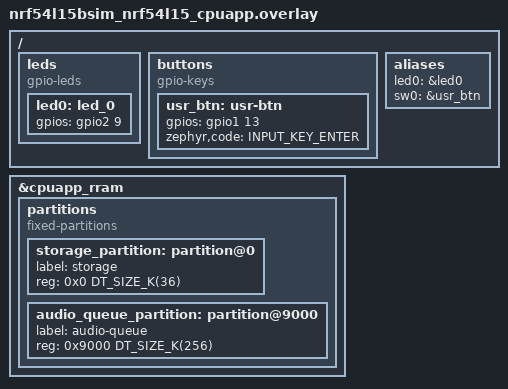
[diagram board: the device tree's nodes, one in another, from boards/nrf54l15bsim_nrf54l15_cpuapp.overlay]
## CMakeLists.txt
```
# Copyright (c) Meta Platforms, Inc. and affiliates.
#
# Licensed under the Apache License, Version 2.0 (the "License");
# you may not use this file except in compliance with the License.
# You may obtain a copy of the License at
#
#     http://www.apache.org/licenses/LICENSE-2.0
#
# Unless required by applicable law or agreed to in writing, software
# distributed under the License is distributed on an "AS IS" BASIS,
# WITHOUT WARRANTIES OR CONDITIONS OF ANY KIND, either express or implied.
# See the License for the specific language governing permissions and
# limitations under the License.

cmake_minimum_required(VERSION 3.20.0)

find_package(Zephyr REQUIRED HINTS $ENV{ZEPHYR_BASE})
project(muse_gadget_zephyr)

# The XIAO's flash map (mcuboot, slot0, slot1, storage) boots through MCUboot:
# without it the image would sit at slot0 with nothing at 0 to start it.
if(CONFIG_BOARD_XIAO_NRF54L15 AND NOT CONFIG_BOOTLOADER_MCUBOOT)
  message(FATAL_ERROR "Build the XIAO nRF54L15 with --sysbuild: it boots through MCUboot "
    "(sysbuild.conf). See AGENTS.md, Build.")
endif()

include(${CMAKE_CURRENT_SOURCE_DIR}/cmake/mg_common.cmake)

target_include_directories(app PRIVATE ${MG_PROTOCOLS} src)

target_sources(app PRIVATE
  src/main.c
  src/mg_core.c
  src/mg_settings.c
  src/mg_session.c
  src/mg_identity.c
  src/mg_json.c
  src/mg_psa.c
  src/mg_setup.c
  src/mg_setup_crypto.c
  src/mg_setup_store.c
  src/mg_token_proof.c
  src/mg_codec.c
  src/mg_audio.c
  src/mg_hpf.c
  src/mg_ble.c
  src/mg_connparam.c
  src/mg_throughput.c
  src/mg_led.c
  src/mg_button.c
)
target_sources_ifdef(CONFIG_MG_AUDIO_QUEUE app PRIVATE src/mg_queue.c)
target_sources_ifdef(CONFIG_MG_SECURE app PRIVATE src/mg_crypto.c src/mg_pairing.c)
target_sources_ifdef(CONFIG_MG_BATTERY_ADC app PRIVATE src/mg_battery.c)
target_sources_ifdef(CONFIG_MG_NUS app PRIVATE src/mg_nus.c)
target_sources_ifdef(CONFIG_MG_DFU app PRIVATE src/mg_ota.c)
target_sources_ifdef(CONFIG_MG_BENCH app PRIVATE src/mg_bench.c)
target_sources_ifdef(CONFIG_MG_AUDIO_SRC_DMIC app PRIVATE src/mg_audio_dmic.c)
target_sources_ifdef(CONFIG_MG_AUDIO_SRC_SYNTH app PRIVATE src/mg_audio_synth.c)
if(CONFIG_MG_BSIM_TESTS)
  add_subdirectory(${ZEPHYR_BASE}/tests/bsim/babblekit babblekit)
  target_link_libraries(app PRIVATE babblekit)
  target_sources(app PRIVATE tests/bsim/gadget_hooks.c)
  zephyr_include_directories(
    $ENV{BSIM_COMPONENTS_PATH}/libUtilv1/src $ENV{BSIM_COMPONENTS_PATH}/libPhyComv1/src)
endif()

mg_add_transcript(app)
mg_add_sbc(app)
if(CONFIG_MG_LC3)
  mg_add_lc3(app)
endif()
```

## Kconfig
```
# Copyright (c) Meta Platforms, Inc. and affiliates.
#
# Licensed under the Apache License, Version 2.0 (the "License");
# you may not use this file except in compliance with the License.
# You may obtain a copy of the License at
#
#     http://www.apache.org/licenses/LICENSE-2.0
#
# Unless required by applicable law or agreed to in writing, software
# distributed under the License is distributed on an "AS IS" BASIS,
# WITHOUT WARRANTIES OR CONDITIONS OF ANY KIND, either express or implied.
# See the License for the specific language governing permissions and
# limitations under the License.

mainmenu "Muse Gadget (Zephyr)"

rsource "Kconfig.mg"

# Device Information Service strings (mgcommands.h). The firmware revision
# is the app version from the VERSION file.
config BT_DIS_FW_REV_STR
	default "$(APPVERSION)"

config BT_DIS_MANUF_NAME_STR
	default "Seeed Studio"

config BT_DIS_MODEL_NUMBER_STR
	default "XIAO nRF54L15"

config BT_DIS_SW_REV_STR
	default "mg1"

# The connection parameters GAP advertises (Peripheral Preferred Connection
# Parameters) are the ones mg_connparam.c asks for.
config BT_PERIPHERAL_PREF_MIN_INT
	default MG_CONN_INTERVAL_MIN

config BT_PERIPHERAL_PREF_MAX_INT
	default MG_CONN_INTERVAL_MAX

config BT_PERIPHERAL_PREF_LATENCY
	default MG_CONN_LATENCY

config BT_PERIPHERAL_PREF_TIMEOUT
	default MG_CONN_TIMEOUT

source "Kconfig.zephyr"
```

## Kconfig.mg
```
# Copyright (c) Meta Platforms, Inc. and affiliates.
#
# Licensed under the Apache License, Version 2.0 (the "License");
# you may not use this file except in compliance with the License.
# You may obtain a copy of the License at
#
#     http://www.apache.org/licenses/LICENSE-2.0
#
# Unless required by applicable law or agreed to in writing, software
# distributed under the License is distributed on an "AS IS" BASIS,
# WITHOUT WARRANTIES OR CONDITIONS OF ANY KIND, either express or implied.
# See the License for the specific language governing permissions and
# limitations under the License.

# Options shared by the app and the tests.

DT_ZEPHYR_USER := /zephyr,user

menu "Muse Gadget"

config MG_DEVICE_NAME_PREFIX
	string "Advertised name prefix"
	default "MuseGadget-"
	help
	  The GAP Device Name is this prefix followed by the last three bytes
	  of the identity address in hex, e.g. MuseGadget-1A2B3C.

config MG_SDK_TOKEN
	string "Muse Gadgets SDK token"
	default ""
	help
	  Your mgst_ SDK token from gadgets.muse.ai (Account > SDK tokens).
	  Muse Link setup hands it to the app in pairing_confirmed, for the
	  device-token mint. Keep it out of committed config files.

config MG_RESET_HOLD_MS
	int "Hold the button this long at power-up to reset setup (ms)"
	default 5000
	help
	  Holding the talk button while powering up, and on for this long,
	  erases what Muse Link setup stored (the device tokens, the token
	  proof key and the setup markers) and advertises Link setup again.

config MG_SBC_BITPOOL
	int "SBC bitpool"
	range 2 128
	default 26
	help
	  SBC at 16 kHz mono, 16 blocks, 8 subbands, loudness allocation.
	  Bitpool 26 gives 60-byte frames every 8 ms (60 kb/s), the same
	  quality point as mSBC.

config MG_LC3
	bool "LC3 codec"
	default y
	help
	  Adds LC3 (16 kHz mono, 10 ms frames) to the start_mic codec list.

config MG_LC3_FRAME_BYTES
	int "LC3 frame size in bytes"
	depends on MG_LC3
	range 20 400
	default 40

config MG_AUDIO_MAX_PACKET_MS
	int "Longest stretch of audio in one Data notification (ms)"
	default 40
	help
	  Whole codec frames are packed into each notification up to the ATT
	  payload size and this much audio, which bounds the added latency.

config MG_MIC_DEFAULT_GAIN
	int "Default mic gain (1-100)"
	range 1 100
	default 50
	help
	  Software gain applied to the PCM before encoding, and what a client's
	  set_mic_gain changes. The scale is gain/12.5, so 50 is +12 dB and 12
	  is about unity.

config MG_MIC_HPF_HZ
	int "DC-blocking high-pass corner (Hz, 0 = off)"
	range 0 200
	default 30
	help
	  A one-pole high-pass right after the microphone, before the gain:
	  PDM microphones start with a large DC offset that drifts for seconds.
	  Primed with the first sample at each start, so the first frames carry
	  no settling step.

config MG_DMIC_HW_GAIN_DB
	int "PDM hardware gain (dB, -20 to +20)"
	range -20 20
	default 10
	depends on NRFX_PDM
	help
	  The nRF PDM peripheral's own gain, in 0.5 dB steps from its 0 dB
	  default, applied before decimation so quiet speech keeps its
	  resolution. +10 dB with the default software gain puts speech from
	  about 30 cm near -20 dBFS on the XIAO nRF54L15 Sense.

config MG_HAPTICS
	bool "The board has a vibration motor"
	help
	  Only boards with a vibration motor list and accept haptics_enabled
	  and the ptt_buzz_* settings (mgcommands.h), so apps show vibration
	  controls only for them. The XIAO has none (its "buzz" is an LED
	  flash): off, those settings answer unsupported.

config MG_ASSISTANT_STATE
	bool "Show the assistant state on the LED"
	default y if $(dt_alias_enabled,led0)
	help
	  Lists mg_command_assistant_state and shows listening, thinking,
	  responding, done and error on the LED.

config MG_STATE_COMPAT_TIMEOUT_MS
	int "Turn timeout for clients that send no assistant_state (ms)"
	depends on MG_ASSISTANT_STATE
	default 15000
	help
	  After stop_mic the LED shows thinking by itself. A client that has
	  sent no assistant_state on this connection and sends none within this
	  time gets done (then idle) instead: older clients never report the
	  turn. Any assistant_state cancels it for the rest of the connection.

choice MG_AUDIO_SRC
	prompt "Audio source"
	default MG_AUDIO_SRC_DMIC if $(dt_nodelabel_enabled,dmic_dev)
	default MG_AUDIO_SRC_SYNTH

config MG_AUDIO_SRC_DMIC
	bool "PDM microphone (DMIC API)"
	select AUDIO
	select AUDIO_DMIC

config MG_AUDIO_SRC_SYNTH
	bool "Synthetic test signal"
	help
	  A deterministic tone pattern at 16 kHz, for simulation and boards
	  without a microphone.

endchoice

config MG_AUDIO_QUEUE
	bool "Offline clip queue"
	default y if $(dt_nodelabel_enabled,audio_queue_partition)
	default y if MG_QUEUE_IN_SLOT1
	select FLASH
	select FLASH_MAP
	select CRC
	help
	  Records push-to-talk utterances to the audio_queue_partition (or
	  MCUboot's secondary slot, MG_QUEUE_IN_SLOT1) while no client is
	  connected (when audio_queue_enabled is set) and serves them with
	  mg_command_audio_queue.

config MG_QUEUE_IN_SLOT1
	bool "Keep offline clips in MCUboot's secondary slot"
	default y if BOOTLOADER_MCUBOOT && $(dt_nodelabel_enabled,slot1_partition)
	help
	  The clip queue lives in slot1_partition, which firmware updates also
	  use: an upload hands it to OTA (dropping the clips), and the queue
	  takes it back once MCUboot needs nothing there (see src/mg_queue.h).

config MG_QUEUE_SLOT1_TRAILER
	hex "Bytes at the end of the slot the queue never writes"
	depends on MG_QUEUE_IN_SLOT1
	default 0x3000
	help
	  MCUboot's image trailer (magic, flags, swap status). With swap using
	  move it is 3 x (sectors per slot) x (write block) bytes of status plus
	  about 80 bytes: 3 x 178 x 16 + 80 = 8.6 KB for the XIAO's 712 KB slot
	  of 4 KB sectors, rounded up to whole sectors.

config MG_DFU
	bool "Firmware updates over BLE (MCUmgr SMP)"
	default y if BOOTLOADER_MCUBOOT && MCUMGR_TRANSPORT_BT && MCUMGR_GRP_IMG
	depends on BOOTLOADER_MCUBOOT
	select MCUMGR_SMP_COMMAND_STATUS_HOOKS
	help
	  MCUmgr's image and OS groups on the SMP GATT service, for nRF Connect
	  Device Manager and mcumgr clients. The app confirms a new image once
	  BLE is up and advertising, so an image that never gets there is
	  reverted at the next reset. Needs a sysbuild build with MCUboot.

choice MG_SMP_ACCESS
	prompt "Who may use MCUmgr SMP"
	depends on MG_DFU
	default MG_SMP_ACCESS_SESSION if MG_SECURE
	default MG_SMP_ACCESS_OPEN

config MG_SMP_ACCESS_OPEN
	bool "Anyone connected"
	help
	  Any connected client can list, upload, test, confirm and reset. For
	  development and plaintext gadgets.

config MG_SMP_ACCESS_SESSION
	bool "Only clients with an authenticated session"
	depends on MG_SECURE
	help
	  SMP commands are answered only while the connection carries an
	  authenticated mgcommands-secure session (a paired client that has
	  proved its key); otherwise every command gets MGMT_ERR_EACCESSDENIED.
	  The Muse app updates the gadget after authenticating; generic SMP
	  tools can't.

endchoice

menu "Connection parameters"

config MG_CONN_INTERVAL_MIN
	int "Connection interval, minimum (1.25 ms units)"
	range 6 3200
	default 12
	help
	  12 is 15 ms. Apple's accessory rules: at least 15 ms, and the maximum
	  at least 15 ms above the minimum unless both are 15 ms.

config MG_CONN_INTERVAL_MAX
	int "Connection interval, maximum (1.25 ms units)"
	range 6 3200
	default 12

config MG_CONN_LATENCY
	int "Peripheral latency (connection events)"
	range 0 30
	default 10
	help
	  Events the gadget may skip while it has nothing to send. Off (0)
	  while the phone streams to it (MG_CONN_LATENCY_HOLD_MS). Apple:
	  at most 30, and interval max x (latency + 1) x 3 below the timeout.

config MG_CONN_TIMEOUT
	int "Supervision timeout (10 ms units)"
	range 10 3200
	default 400
	help
	  400 is 4 s (Apple: 2 to 6 s).

config MG_CONN_LATENCY_HOLD_MS
	int "Latency stays off this long after the last phone->device data (ms)"
	default 2000

endmenu

config MG_BENCH_NO_CONFIRM
	bool "Never confirm a new image (revert test)"
	depends on MG_DFU
	help
	  Bench builds only: the app doesn't confirm an image running on test,
	  so MCUboot swaps the previous image back at the next reset. Build a
	  test image with it to show a revert; never ship it.

config MG_BENCH
	bool "Bench console"
	select CONSOLE_SUBSYS
	help
	  Single-key commands on the console UART, for testing without a phone
	  or a hand on the button: d / u press and release the talk button
	  through the real button path, s prints the status. Normal builds keep
	  the console output-only.

config MG_AUDIO_QUEUE_MAX_CLIPS
	int "Most clips the queue holds"
	depends on MG_AUDIO_QUEUE
	default 128

config MG_BATTERY_ADC
	bool "Read the battery voltage with the ADC"
	default y if $(dt_node_has_prop,$(DT_ZEPHYR_USER),io-channels)
	select ADC
	help
	  Without it, Battery Level reads 100.

config MG_BATTERY_DIVIDER_RATIO
	int "Battery divider ratio (VBAT / pin voltage)"
	depends on MG_BATTERY_ADC
	default 2

config MG_NUS
	bool "Nordic UART Service log mirror and console"
	default y
	select BT_ZEPHYR_NUS
	select RING_BUFFER

config MG_SECURE
	bool "Session security (mgcommands-secure.h)"
	select PSA_CRYPTO
	select PSA_WANT_ALG_ECDH
	select PSA_WANT_ECC_MONTGOMERY_255
	select PSA_WANT_KEY_TYPE_ECC_KEY_PAIR_GENERATE
	select PSA_WANT_KEY_TYPE_ECC_KEY_PAIR_IMPORT
	select PSA_WANT_KEY_TYPE_ECC_KEY_PAIR_EXPORT
	select PSA_WANT_KEY_TYPE_ECC_PUBLIC_KEY
	select PSA_WANT_ALG_SHA_256
	select PSA_WANT_ALG_HMAC
	select PSA_WANT_KEY_TYPE_HMAC
	select PSA_WANT_ALG_GCM
	select PSA_WANT_KEY_TYPE_AES
	help
	  Key exchange, application-layer AES-256-GCM on the Encrypted
	  Control and Encrypted Data characteristics, physical_confirm pairing
	  with the button, and pairing keys persisted with Zephyr settings.

config MG_SECURE_MAX_PAIRINGS
	int "Stored pairings"
	depends on MG_SECURE
	default 4

config MG_LINK_SETUP_CRYPTO
	bool
	default y
	select PSA_CRYPTO
	select PSA_WANT_ALG_ECDH
	select PSA_WANT_ECC_SECP_R1_256
	select PSA_WANT_KEY_TYPE_ECC_KEY_PAIR_GENERATE
	select PSA_WANT_KEY_TYPE_ECC_KEY_PAIR_IMPORT
	select PSA_WANT_KEY_TYPE_ECC_KEY_PAIR_EXPORT
	select PSA_WANT_KEY_TYPE_ECC_PUBLIC_KEY
	select PSA_WANT_ALG_SHA_256
	select PSA_WANT_ALG_HMAC
	select PSA_WANT_KEY_TYPE_HMAC
	select PSA_WANT_ALG_GCM
	select PSA_WANT_KEY_TYPE_AES
	help
	  Muse Link setup (P-256 ECDH, HKDF-SHA256, AES-256-GCM) and the
	  token proof (HMAC-SHA256), on PSA Crypto.

config MG_BSIM_TESTS
	bool "BabbleSim test hooks"
	depends on SOC_SERIES_BSIM_NRFXX
	help
	  Adds the bstest entry points used by tests/bsim to press the button
	  from the simulation.

module = MG
module-str = Muse Gadget
source "subsys/logging/Kconfig.template.log_config"

endmenu
```

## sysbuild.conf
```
# Copyright (c) Meta Platforms, Inc. and affiliates.
#
# Licensed under the Apache License, Version 2.0 (the "License");
# you may not use this file except in compliance with the License.
# You may obtain a copy of the License at
#
#     http://www.apache.org/licenses/LICENSE-2.0
#
# Unless required by applicable law or agreed to in writing, software
# distributed under the License is distributed on an "AS IS" BASIS,
# WITHOUT WARRANTIES OR CONDITIONS OF ANY KIND, either express or implied.
# See the License for the specific language governing permissions and
# limitations under the License.


# The XIAO nRF54L15 boots through MCUboot (build with --sysbuild). Swap using
# move keeps test, confirm and revert: a new image runs on test, the app
# confirms it once BLE is up, and an image that never gets there is swapped
# back at the next reset. The image is signed with MCUboot's ECDSA P-256
# development key (bootloader/mcuboot/root-ec-p256.pem): anyone can sign for
# it, so production builds must set SB_CONFIG_BOOT_SIGNATURE_KEY_FILE to
# their own key (and keep it out of the repository).
SB_CONFIG_BOOTLOADER_MCUBOOT=y
SB_CONFIG_MCUBOOT_MODE_SWAP_USING_MOVE=y
SB_CONFIG_BOOT_SIGNATURE_TYPE_ECDSA_P256=y
```

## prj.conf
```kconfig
# Copyright (c) Meta Platforms, Inc. and affiliates.
#
# Licensed under the Apache License, Version 2.0 (the "License");
# you may not use this file except in compliance with the License.
# You may obtain a copy of the License at
#
#     http://www.apache.org/licenses/LICENSE-2.0
#
# Unless required by applicable law or agreed to in writing, software
# distributed under the License is distributed on an "AS IS" BASIS,
# WITHOUT WARRANTIES OR CONDITIONS OF ANY KIND, either express or implied.
# See the License for the specific language governing permissions and
# limitations under the License.

# Bluetooth: one peripheral connection, large MTU and data length for audio.
CONFIG_BT=y
CONFIG_BT_PERIPHERAL=y
CONFIG_BT_MAX_CONN=1
CONFIG_BT_GATT_CLIENT=y
CONFIG_BT_DEVICE_NAME="MuseGadget"
CONFIG_BT_DEVICE_NAME_DYNAMIC=y
CONFIG_BT_DEVICE_NAME_MAX=32
CONFIG_BT_DEVICE_APPEARANCE=0
CONFIG_BT_L2CAP_TX_MTU=247
CONFIG_BT_BUF_ACL_RX_SIZE=251
CONFIG_BT_BUF_ACL_TX_SIZE=251
CONFIG_BT_BUF_ACL_TX_COUNT=12
# Phone->device headroom (an SMP upload, set_tokens): the controller
# defaults to one RX PDU buffer and the host to two ACL buffers, and when
# the host can't drain them as fast as PDUs arrive (an image flash write
# running) the controller NACKs the rest of the connection event. In
# BabbleSim the host keeps up either way (163 KB/s received with 1 or 8);
# eight of each cost about 4 KB.
CONFIG_BT_CTLR_RX_BUFFERS=8
CONFIG_BT_BUF_ACL_RX_COUNT_EXTRA=7
CONFIG_BT_BUF_EVT_RX_COUNT=16
# Every board this app builds for (the XIAO and any other nRF54L15) asks
# for 251-byte link-layer PDUs and the 2M PHY right after connecting
# (mg_ble.c) and logs what it gets; the controller's 2M PHY
# (CONFIG_BT_CTLR_PHY_2M) is on by default.
CONFIG_BT_CTLR_DATA_LENGTH_MAX=251
CONFIG_BT_USER_DATA_LEN_UPDATE=y
CONFIG_BT_USER_PHY_UPDATE=y
CONFIG_BT_CTLR_PHY_2M=y
# mg_connparam.c asks for the connection parameters itself (15 ms, latency
# 10, 4 s; latency off while the phone streams to the gadget), so the host
# doesn't send its own update. CONFIG_MG_CONN_* sets them, and the GAP
# preferred parameters follow (Kconfig).
CONFIG_BT_GAP_AUTO_UPDATE_CONN_PARAMS=n
# The host holds a peripheral's parameter requests back this long after
# connecting (the Core spec's TGAP(conn_pause_peripheral) is 1 s; Zephyr's
# default is 5 s, past most of a phone's setup traffic).
CONFIG_BT_CONN_PARAM_UPDATE_TIMEOUT=1000
CONFIG_BT_RX_STACK_SIZE=2560

# Standard services.
CONFIG_BT_BAS=y
CONFIG_BT_DIS=y
CONFIG_BT_DIS_PNP=n
CONFIG_BT_DIS_MODEL_NUMBER=y
CONFIG_BT_DIS_MANUF_NAME=y
CONFIG_BT_DIS_FW_REV=y
CONFIG_BT_DIS_SW_REV=y

# Settings (push-to-talk, codec, haptics, queue) in ZMS.
CONFIG_FLASH=y
CONFIG_FLASH_MAP=y
CONFIG_ZMS=y
CONFIG_SETTINGS=y
CONFIG_SETTINGS_ZMS=y
# PSA key slots: Link setup holds at most two keys at a time.
CONFIG_MBEDTLS_PSA_KEY_SLOT_COUNT=4

# Offline clip checksums.
CONFIG_CRC=y

# Button through the input subsystem (gpio-keys debounces).
CONFIG_INPUT=y
CONFIG_GPIO=y

CONFIG_LOG=y
CONFIG_MAIN_STACK_SIZE=2048
CONFIG_SYSTEM_WORKQUEUE_STACK_SIZE=2048
```

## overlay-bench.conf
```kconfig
# Copyright (c) Meta Platforms, Inc. and affiliates.
#
# Licensed under the Apache License, Version 2.0 (the "License");
# you may not use this file except in compliance with the License.
# You may obtain a copy of the License at
#
#     http://www.apache.org/licenses/LICENSE-2.0
#
# Unless required by applicable law or agreed to in writing, software
# distributed under the License is distributed on an "AS IS" BASIS,
# WITHOUT WARRANTIES OR CONDITIONS OF ANY KIND, either express or implied.
# See the License for the specific language governing permissions and
# limitations under the License.


# Bench build: single-key commands on the console UART (uart20, the XIAO's
# USB serial port): d / u press and release the talk button, s prints the
# status. -DEXTRA_CONF_FILE=overlay-bench.conf.
CONFIG_MG_BENCH=y
CONFIG_CONSOLE_GETCHAR=y
```

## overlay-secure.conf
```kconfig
# Copyright (c) Meta Platforms, Inc. and affiliates.
#
# Licensed under the Apache License, Version 2.0 (the "License");
# you may not use this file except in compliance with the License.
# You may obtain a copy of the License at
#
#     http://www.apache.org/licenses/LICENSE-2.0
#
# Unless required by applicable law or agreed to in writing, software
# distributed under the License is distributed on an "AS IS" BASIS,
# WITHOUT WARRANTIES OR CONDITIONS OF ANY KIND, either express or implied.
# See the License for the specific language governing permissions and
# limitations under the License.

# Session security (mgcommands-secure.h).
CONFIG_MG_SECURE=y
CONFIG_MBEDTLS_PSA_KEY_SLOT_COUNT=16
```

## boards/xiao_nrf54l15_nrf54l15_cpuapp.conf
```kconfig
# Copyright (c) Meta Platforms, Inc. and affiliates.
#
# Licensed under the Apache License, Version 2.0 (the "License");
# you may not use this file except in compliance with the License.
# You may obtain a copy of the License at
#
#     http://www.apache.org/licenses/LICENSE-2.0
#
# Unless required by applicable law or agreed to in writing, software
# distributed under the License is distributed on an "AS IS" BASIS,
# WITHOUT WARRANTIES OR CONDITIONS OF ANY KIND, either express or implied.
# See the License for the specific language governing permissions and
# limitations under the License.


CONFIG_FPU=y

# Firmware updates over BLE: MCUmgr SMP (image and OS groups) beside the mg
# service, with MCUboot from sysbuild (sysbuild.conf). The image lives in
# slot0; MG_DFU confirms test images and shares slot1 with the clip queue.
CONFIG_MCUMGR=y
CONFIG_NET_BUF=y
CONFIG_ZCBOR=y
CONFIG_CRC=y
CONFIG_FLASH=y
CONFIG_FLASH_MAP=y
CONFIG_STREAM_FLASH=y
CONFIG_IMG_MANAGER=y
CONFIG_MCUBOOT_IMG_MANAGER=y
CONFIG_MCUMGR_GRP_IMG=y
CONFIG_MCUMGR_GRP_IMG_STATUS_HOOKS=y
CONFIG_MCUMGR_GRP_OS=y
CONFIG_MCUMGR_GRP_OS_ECHO=y
CONFIG_MCUMGR_GRP_OS_INFO=y
CONFIG_MCUMGR_MGMT_NOTIFICATION_HOOKS=y
CONFIG_MCUMGR_TRANSPORT_BT=y
# Throughput: one SMP request spans many ATT writes (reassembly) into a
# 2475-byte buffer, which clients learn from the OS group's MCUmgr
# parameters (buf_size, buf_count) and fill: about 2.4 KB of image per
# request instead of one ATT write's 200 B. Four buffers let a client keep
# two requests in flight (one more is the response). The image is written
# in 4 KB blocks, so each request costs at most one wait for a gap in the
# radio schedule (CONFIG_SOC_FLASH_NRF_RADIO_SYNC_TICKER) instead of five.
CONFIG_MCUMGR_TRANSPORT_BT_REASSEMBLY=y
CONFIG_MCUMGR_TRANSPORT_NETBUF_SIZE=2475
CONFIG_MCUMGR_TRANSPORT_NETBUF_COUNT=4
CONFIG_MCUMGR_GRP_OS_MCUMGR_PARAMS=y
CONFIG_IMG_BLOCK_BUF_SIZE=4096
CONFIG_MCUMGR_TRANSPORT_WORKQUEUE_STACK_SIZE=4096
```

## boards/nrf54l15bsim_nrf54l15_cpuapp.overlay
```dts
/*
 * Copyright (c) Meta Platforms, Inc. and affiliates.
 *
 * Licensed under the Apache License, Version 2.0 (the "License");
 * you may not use this file except in compliance with the License.
 * You may obtain a copy of the License at
 *
 *     http://www.apache.org/licenses/LICENSE-2.0
 *
 * Unless required by applicable law or agreed to in writing, software
 * distributed under the License is distributed on an "AS IS" BASIS,
 * WITHOUT WARRANTIES OR CONDITIONS OF ANY KIND, either express or implied.
 * See the License for the specific language governing permissions and
 * limitations under the License.
 */

/*
 * BabbleSim nRF54L15. No PDM model: the synthetic source stands in for the
 * microphone, and the test hooks press the button. The 512 KiB storage
 * partition is split into settings and the offline clip queue.
 */

/ {
	leds {
		compatible = "gpio-leds";
		led0: led_0 {
			gpios = <&gpio2 9 GPIO_ACTIVE_HIGH>;
		};
	};

	/* The GPIO model has no pull resistors: an active-low button would read
	 * pressed at boot (and take the setup-reset hold). Presses come from
	 * the test hooks (mg_button_inject), not the pin. */
	buttons {
		compatible = "gpio-keys";
		usr_btn: usr-btn {
			gpios = <&gpio1 13 GPIO_ACTIVE_HIGH>;
			zephyr,code = <INPUT_KEY_ENTER>;
		};
	};

	aliases {
		led0 = &led0;
		sw0 = &usr_btn;
	};
};

/delete-node/ &storage_partition;

&cpuapp_rram {
	partitions {
		compatible = "fixed-partitions";
		#address-cells = <1>;
		#size-cells = <1>;

		storage_partition: partition@0 {
			label = "storage";
			reg = <0x0 DT_SIZE_K(36)>;
		};

		audio_queue_partition: partition@9000 {
			label = "audio-queue";
			reg = <0x9000 DT_SIZE_K(256)>;
		};
	};
};
```

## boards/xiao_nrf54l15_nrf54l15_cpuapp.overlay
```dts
/*
 * Copyright (c) Meta Platforms, Inc. and affiliates.
 *
 * Licensed under the Apache License, Version 2.0 (the "License");
 * you may not use this file except in compliance with the License.
 * You may obtain a copy of the License at
 *
 *     http://www.apache.org/licenses/LICENSE-2.0
 *
 * Unless required by applicable law or agreed to in writing, software
 * distributed under the License is distributed on an "AS IS" BASIS,
 * WITHOUT WARRANTIES OR CONDITIONS OF ANY KIND, either express or implied.
 * See the License for the specific language governing permissions and
 * limitations under the License.
 */

/*
 * Seeed XIAO nRF54L15 (Sense). The Sense's PDM microphone is on pdm20
 * (dmic_dev in the board file), the user button is sw0 and the LED led0.
 *
 * The RRAM keeps the board's standard MCUboot map (nrf54l15_cpuapp_partition.dtsi):
 * mcuboot 62 KB at 0, slot0 712 KB at 0x10000, slot1 712 KB at 0xc2000 and
 * storage (settings) 36 KB at 0x174000. slot1 doubles as the offline clip
 * queue while no firmware update needs it (src/mg_queue.h).
 */

/ {
	zephyr,user {
		/* VBAT through the board's 2:1 divider, switched on by P1.15 (vbat_pwr,
		 * on from boot), on AIN7: channel 7 of the board's ADC node. */
		io-channels = <&adc 7>;
	};
};
```

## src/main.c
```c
/*
 * Copyright (c) Meta Platforms, Inc. and affiliates.
 *
 * Licensed under the Apache License, Version 2.0 (the "License");
 * you may not use this file except in compliance with the License.
 * You may obtain a copy of the License at
 *
 *     http://www.apache.org/licenses/LICENSE-2.0
 *
 * Unless required by applicable law or agreed to in writing, software
 * distributed under the License is distributed on an "AS IS" BASIS,
 * WITHOUT WARRANTIES OR CONDITIONS OF ANY KIND, either express or implied.
 * See the License for the specific language governing permissions and
 * limitations under the License.
 */

#include <errno.h>

#include <zephyr/kernel.h>
#include <zephyr/logging/log.h>
#include <zephyr/settings/settings.h>

#include "mg_app.h"
#include "mg_audio.h"
#include "mg_button.h"
#include "mg_core.h"
#include "mg_led.h"
#if defined(CONFIG_MG_DFU)
#include "mg_ota.h"
#endif
#include "mg_session.h"
#include "mg_settings.h"
#include "mg_setup.h"
#include "mg_setup_store.h"
#include "mg_transport.h"
#if defined(CONFIG_MG_AUDIO_QUEUE)
#include "mg_queue.h"
#endif
#if defined(CONFIG_MG_BATTERY_ADC)
#include "mg_battery.h"
#endif

LOG_MODULE_REGISTER(mg_main, CONFIG_MG_LOG_LEVEL);

/* Link setup runs P-256 ECDH (mbedTLS) on this queue. */
K_THREAD_STACK_DEFINE(app_stack, 6144);
static struct k_work_q app_wq;

struct k_work_q *mg_app_wq(void)
{
	return &app_wq;
}

const char *mg_app_version(void)
{
	return CONFIG_BT_DIS_FW_REV_STR;
}

static uint8_t battery = 100;
static int battery_mv = -ENODEV;
static struct k_work_delayable battery_work;

uint8_t mg_app_battery_percent(void)
{
	return battery;
}

int mg_app_battery_mv(void)
{
	return battery_mv;
}

/* Below this, no cell is connected (or it's flat beyond use): Battery Level
 * reports 100, as for a gadget without one. */
#define NO_BATTERY_MV 2500

static void battery_fn(struct k_work *w)
{
	ARG_UNUSED(w);
#if defined(CONFIG_MG_BATTERY_ADC)
	int mv = mg_battery_read_mv();

	battery_mv = mv;
	if (mv >= NO_BATTERY_MV) {
		battery = mg_battery_percent_from_mv(mv);
	} else {
		battery = 100;
	}
	LOG_DBG("battery %d mV, %u%%", mv, battery);
#endif
	mg_ble_set_battery(battery);
	k_work_reschedule(&battery_work, K_SECONDS(60));
}

/* Held at power-up and still held CONFIG_MG_RESET_HOLD_MS later: reset. */
static bool held_for_reset(void)
{
	LOG_INF("button held at power-up: keep holding %d s to reset setup",
		CONFIG_MG_RESET_HOLD_MS / 1000);
	for (int t = 0; t < CONFIG_MG_RESET_HOLD_MS; t += 100) {
		k_sleep(K_MSEC(100));
		if (!mg_button_held_at_boot()) {
			LOG_INF("released: no reset");
			return false;
		}
	}
	return true;
}

int main(void)
{
	bool held;

	LOG_INF("Muse Gadget %s starting (mg%d)", mg_app_version(), MG_SPEC_VERSION);
	k_work_queue_start(&app_wq, app_stack, K_THREAD_STACK_SIZEOF(app_stack),
			   K_PRIO_PREEMPT(5), NULL);
	k_thread_name_set(&app_wq.thread, "mg_app");

	mg_led_init();
	held = mg_button_held_at_boot();
	mg_button_init();

	if (settings_subsys_init()) {
		LOG_ERR("settings unavailable; using defaults");
	}
	(void)mg_settings_load();
	(void)mg_setup_store_load();
	if (held && held_for_reset()) {
		(void)mg_setup_factory_reset("button held at power-up");
	}
#if defined(CONFIG_MG_AUDIO_QUEUE)
	(void)mg_queue_init();
#endif
#if defined(CONFIG_MG_DFU)
	mg_ota_init();
#endif
	mg_core_init();
	mg_audio_init();

	if (mg_ble_init()) {
		return 0;
	}
	/* After BLE: the identity comes from the address. */
	mg_setup_init();
	/* Held at power-up: pairing mode too (mgcommands-secure.h). */
	mg_session_init(held);
	mg_core_link_refresh();
#if defined(CONFIG_MG_NUS)
	mg_nus_init();
#endif
	k_work_init_delayable(&battery_work, battery_fn);
	k_work_reschedule(&battery_work, K_NO_WAIT);
	int err = mg_ble_start_advertising();

#if defined(CONFIG_MG_DFU)
	if (!err) {
		/* Healthy: keep this image (and take the clip store back). */
		mg_ota_healthy();
	}
#endif
#if defined(CONFIG_MG_BENCH)
	mg_bench_init();
#endif
	ARG_UNUSED(err);
	return 0;
}
```

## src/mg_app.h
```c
/*
 * Copyright (c) Meta Platforms, Inc. and affiliates.
 *
 * Licensed under the Apache License, Version 2.0 (the "License");
 * you may not use this file except in compliance with the License.
 * You may obtain a copy of the License at
 *
 *     http://www.apache.org/licenses/LICENSE-2.0
 *
 * Unless required by applicable law or agreed to in writing, software
 * distributed under the License is distributed on an "AS IS" BASIS,
 * WITHOUT WARRANTIES OR CONDITIONS OF ANY KIND, either express or implied.
 * See the License for the specific language governing permissions and
 * limitations under the License.
 */

#ifndef MG_APP_H_
#define MG_APP_H_

#include <stdint.h>

const char *mg_app_version(void);
uint8_t mg_app_battery_percent(void);
/* The last battery reading in mV, or <0 without one. */
int mg_app_battery_mv(void);

/* mg_bench.c (CONFIG_MG_BENCH) */
void mg_bench_init(void);

/* mg_ble.c */
int mg_ble_init(void);
int mg_ble_start_advertising(void);
/* Re-reads what to advertise (Link setup or not) and applies it. */
void mg_ble_refresh_advertising(void);
void mg_ble_set_battery(uint8_t percent);

/* mg_nus.c */
void mg_nus_init(void);

#endif
```

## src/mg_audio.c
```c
/*
 * Copyright (c) Meta Platforms, Inc. and affiliates.
 *
 * Licensed under the Apache License, Version 2.0 (the "License");
 * you may not use this file except in compliance with the License.
 * You may obtain a copy of the License at
 *
 *     http://www.apache.org/licenses/LICENSE-2.0
 *
 * Unless required by applicable law or agreed to in writing, software
 * distributed under the License is distributed on an "AS IS" BASIS,
 * WITHOUT WARRANTIES OR CONDITIONS OF ANY KIND, either express or implied.
 * See the License for the specific language governing permissions and
 * limitations under the License.
 */

#include "mg_audio.h"

#include <errno.h>
#include <string.h>

#include <zephyr/kernel.h>
#include <zephyr/logging/log.h>

#include "mg_core.h"
#include "mg_hpf.h"
#include "mg_led.h"
#include "mg_session.h"
#include "mg_settings.h"
#include "mg_transport.h"
#if defined(CONFIG_MG_AUDIO_QUEUE)
#include "mg_queue.h"
#endif

LOG_MODULE_REGISTER(mg_audio, CONFIG_MG_LOG_LEVEL);

#define STACK_SIZE 6144
#define MAX_CHUNK  244

struct request {
	enum mg_audio_activity want;
	uint8_t codec;
	bool ptt;
	uint16_t clip;
	uint32_t gen;
};

static K_MUTEX_DEFINE(lock);
static K_SEM_DEFINE(wake, 0, 1);
static struct request req;
static struct mg_audio_format cur_fmt;
static atomic_t gain_q8;

static int16_t block[MG_AUDIO_BLOCK_SAMPLES];
static int16_t acc[MG_AUDIO_BLOCK_SAMPLES + MG_CODEC_MAX_FRAME_SAMPLES];
static uint8_t frame[MG_CODEC_MAX_FRAME_BYTES];
static uint8_t chunk[MAX_CHUNK];

static struct k_work idle_work;

static void idle_fn(struct k_work *w)
{
	ARG_UNUSED(w);
	mg_core_audio_idle();
}

static uint32_t submit(enum mg_audio_activity want, uint8_t codec, bool ptt, uint16_t clip)
{
	uint32_t gen;

	k_mutex_lock(&lock, K_FOREVER);
	req.want = want;
	req.codec = codec;
	req.ptt = ptt;
	req.clip = clip;
	gen = ++req.gen;
	k_mutex_unlock(&lock);
	k_sem_give(&wake);
	return gen;
}

static bool current(uint32_t gen)
{
	k_mutex_lock(&lock, K_FOREVER);
	bool same = req.gen == gen;

	k_mutex_unlock(&lock);
	return same;
}

int mg_audio_start_live(uint8_t codec, bool ptt)
{
	struct mg_audio_format fmt;

	if (mg_codec_format(codec, &fmt)) {
		return -ENOTSUP;
	}
	submit(MG_AUDIO_LIVE, codec, ptt, 0);
	return 0;
}

int mg_audio_start_recording(uint8_t codec)
{
	struct mg_audio_format fmt;

	if (!IS_ENABLED(CONFIG_MG_AUDIO_QUEUE) || mg_codec_format(codec, &fmt)) {
		return -ENOTSUP;
	}
	submit(MG_AUDIO_RECORDING, codec, false, 0);
	return 0;
}

int mg_audio_read_clip(uint16_t index)
{
	if (!IS_ENABLED(CONFIG_MG_AUDIO_QUEUE)) {
		return -ENOTSUP;
	}
	submit(MG_AUDIO_CLIP, 0, false, index);
	return 0;
}

void mg_audio_stop(void)
{
	submit(MG_AUDIO_IDLE, 0, false, 0);
}

enum mg_audio_activity mg_audio_activity(void)
{
	k_mutex_lock(&lock, K_FOREVER);
	enum mg_audio_activity a = req.want;

	k_mutex_unlock(&lock);
	return a;
}

void mg_audio_current_format(struct mg_audio_format *fmt)
{
	k_mutex_lock(&lock, K_FOREVER);
	*fmt = cur_fmt;
	k_mutex_unlock(&lock);
	if (fmt->type == mg_data_type_unknown) {
		(void)mg_codec_format(mg_settings_get()->audio_codec, fmt);
	}
}

void mg_audio_set_gain(uint8_t gain)
{
	/* gain / 12.5 in Q8. */
	atomic_set(&gain_q8, (atomic_val_t)gain * 2048 / 100);
}

static struct mg_hpf hpf;

static void apply_gain(int16_t *pcm, size_t n)
{
	int32_t g = (int32_t)atomic_get(&gain_q8);

	for (size_t i = 0; i < n; i++) {
		int32_t v = (pcm[i] * g) >> 8;

		pcm[i] = (int16_t)CLAMP(v, INT16_MIN, INT16_MAX);
	}
}

static void announce(const struct mg_audio_format *fmt)
{
	uint8_t buf[9];
	size_t n = mg_codec_change_data_type(fmt, buf);

	k_mutex_lock(&lock, K_FOREVER);
	cur_fmt = *fmt;
	k_mutex_unlock(&lock);
	(void)mg_session_send_control(buf, n);
}

static size_t frames_per_chunk(const struct mg_audio_format *fmt)
{
	size_t room = MIN(mg_session_data_room(), sizeof(chunk));
	size_t by_time = MAX(1, CONFIG_MG_AUDIO_MAX_PACKET_MS * 1000 / fmt->frame_us);

	return MIN(room / fmt->frame_bytes, by_time);
}

static void run_capture(const struct request *r)
{
	struct mg_audio_format fmt;
	size_t nacc = 0, clen = 0, nframes = 0, fpc = 0;
	uint32_t sent = 0, dropped = 0, stored = 0;
	bool live = r->want == MG_AUDIO_LIVE;
	bool full = false;

	if (mg_codec_format(r->codec, &fmt) || mg_codec_open(r->codec)) {
		LOG_ERR("codec %u unavailable", r->codec);
		return;
	}
	if (live) {
		announce(&fmt);
		mg_led_set(MG_LED_STREAMING, true);
	} else {
#if defined(CONFIG_MG_AUDIO_QUEUE)
		int err = mg_queue_begin(r->codec, k_uptime_get_32());

		if (err) {
			LOG_WRN("queue: can't record (%d)", err);
			return;
		}
#endif
		mg_led_set(MG_LED_RECORDING, true);
	}
	if (mg_audio_src_start()) {
		LOG_ERR("audio source failed to start");
		goto out;
	}
	LOG_INF("%s capture, codec %u", live ? "live" : "offline", r->codec);
	/* The first block primes the DC blocker: no settling step at the start. */
	mg_hpf_reset(&hpf);

	while (current(r->gen)) {
		if (mg_audio_src_read(block, 200)) {
			continue;
		}
		mg_hpf_run(&hpf, block, MG_AUDIO_BLOCK_SAMPLES);
		apply_gain(block, MG_AUDIO_BLOCK_SAMPLES);
		memcpy(&acc[nacc], block, sizeof(block));
		nacc += MG_AUDIO_BLOCK_SAMPLES;

		while (nacc >= fmt.frame_samples) {
			int n = mg_codec_encode(acc, frame, sizeof(frame));

			nacc -= fmt.frame_samples;
			memmove(acc, &acc[fmt.frame_samples], nacc * sizeof(acc[0]));
			if (n <= 0) {
				continue;
			}
			if (!live) {
#if defined(CONFIG_MG_AUDIO_QUEUE)
				if (!full && mg_queue_append(frame, n) == -ENOSPC) {
					LOG_WRN("queue full");
					full = true;
				}
				stored += full ? 0 : n;
#endif
				continue;
			}
			if (nframes == 0) {
				fpc = frames_per_chunk(&fmt);
				if (fpc == 0) {
					dropped++;
					continue; /* MTU too small for one frame */
				}
			}
			memcpy(&chunk[clen], frame, n);
			clen += n;
			if (++nframes == fpc) {
				if (mg_session_send_data(chunk, clen, K_NO_WAIT) == 0) {
					sent++;
				} else {
					dropped++;
				}
				clen = 0;
				nframes = 0;
			}
		}
	}
	mg_audio_src_stop();
	if (live && clen) {
		if (mg_session_send_data(chunk, clen, K_MSEC(100)) == 0) {
			sent++;
		} else {
			dropped++;
		}
	}
	LOG_INF("capture ended: %u chunks sent, %u dropped, %u bytes stored", sent, dropped,
		stored);
out:
	if (live) {
		static const uint8_t stop[] = {mg_command_stop_mic};

		/* stop_mic ends every capture, whichever side started it. */
		mg_led_set(MG_LED_STREAMING, false);
		(void)mg_session_send_control(stop, sizeof(stop));
	} else {
#if defined(CONFIG_MG_AUDIO_QUEUE)
		(void)mg_queue_end();
#endif
		mg_led_set(MG_LED_RECORDING, false);
	}
}

#if defined(CONFIG_MG_AUDIO_QUEUE)
static void run_clip(const struct request *r)
{
	struct mg_clip_info ci;
	struct mg_audio_format fmt = {.type = mg_data_type_audio_queue};
	uint32_t off = 0;

	if (mg_queue_clip_info(r->clip, &ci)) {
		return;
	}
	announce(&fmt);
	LOG_INF("sending clip %u (%u bytes)", r->clip, ci.bytes);
	int64_t t0 = k_uptime_get();
	uint32_t chunks = 0;

	while (off < ci.bytes && current(r->gen)) {
		size_t n = MIN(MIN(mg_session_data_room(), sizeof(chunk)), ci.bytes - off);

		if (n == 0 || mg_queue_read(r->clip, off, chunk, n)) {
			break;
		}
		int err = mg_session_send_data(chunk, n, K_MSEC(200));

		if (err == -ENOMEM) {
			continue; /* congested: retry the same chunk */
		}
		if (err) {
			LOG_WRN("clip download stopped (%d)", err);
			break;
		}
		off += n;
		chunks++;
	}
	uint32_t ms = MAX((uint32_t)(k_uptime_get() - t0), 1U);

	/* Queued, not on the air yet: the notification queue holds most of a clip, so
	 * the bench client times the download itself. */
	LOG_INF("clip %u: %u of %u bytes queued in %u ms (%u notifications)", r->clip, off,
		ci.bytes, ms, chunks);
}
#endif

static void audio_thread(void *a, void *b, void *c)
{
	struct request r;

	ARG_UNUSED(a);
	ARG_UNUSED(b);
	ARG_UNUSED(c);
	for (;;) {
		k_sem_take(&wake, K_FOREVER);
		for (;;) {
			k_mutex_lock(&lock, K_FOREVER);
			r = req;
			k_mutex_unlock(&lock);

			switch (r.want) {
			case MG_AUDIO_LIVE:
			case MG_AUDIO_RECORDING:
				run_capture(&r);
				break;
#if defined(CONFIG_MG_AUDIO_QUEUE)
			case MG_AUDIO_CLIP:
				run_clip(&r);
				break;
#endif
			default:
				break;
			}
			/* Finished on its own, or stopped: go idle unless something
			 * new arrived meanwhile. */
			k_mutex_lock(&lock, K_FOREVER);
			bool again = req.gen != r.gen && req.want != MG_AUDIO_IDLE;

			if (!again) {
				req.want = MG_AUDIO_IDLE;
			}
			k_mutex_unlock(&lock);
			if (!again) {
				break;
			}
		}
		k_work_submit_to_queue(mg_app_wq(), &idle_work);
	}
}

K_THREAD_STACK_DEFINE(audio_stack, STACK_SIZE);
static struct k_thread audio_tid;

void mg_audio_init(void)
{
	k_work_init(&idle_work, idle_fn);
	mg_hpf_init(&hpf, CONFIG_MG_MIC_HPF_HZ, 16000);
	k_thread_create(&audio_tid, audio_stack, K_THREAD_STACK_SIZEOF(audio_stack), audio_thread,
			NULL, NULL, NULL, K_PRIO_PREEMPT(4), 0, K_NO_WAIT);
	k_thread_name_set(&audio_tid, "mg_audio");
}
```

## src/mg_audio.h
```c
/*
 * Copyright (c) Meta Platforms, Inc. and affiliates.
 *
 * Licensed under the Apache License, Version 2.0 (the "License");
 * you may not use this file except in compliance with the License.
 * You may obtain a copy of the License at
 *
 *     http://www.apache.org/licenses/LICENSE-2.0
 *
 * Unless required by applicable law or agreed to in writing, software
 * distributed under the License is distributed on an "AS IS" BASIS,
 * WITHOUT WARRANTIES OR CONDITIONS OF ANY KIND, either express or implied.
 * See the License for the specific language governing permissions and
 * limitations under the License.
 */

#ifndef MG_AUDIO_H_
#define MG_AUDIO_H_

#include <stdbool.h>
#include <stdint.h>

#include "mg_codec.h"

enum mg_audio_activity {
	MG_AUDIO_IDLE,
	MG_AUDIO_LIVE,
	MG_AUDIO_RECORDING,
	MG_AUDIO_CLIP,
};

/*
 * The audio thread produces everything on Data: live capture, offline
 * recording into the queue, and clip downloads. It sends change_data_type
 * before a stream's first Data chunk and stop_mic after a live stream's
 * last, so Control and Data stay in order. Starting anything stops
 * what was running first. mg_core_audio_idle() runs when it goes idle.
 */

int mg_audio_start_live(uint8_t codec, bool ptt);
int mg_audio_start_recording(uint8_t codec);
int mg_audio_read_clip(uint16_t index);
/* Ends capture (flushing the last chunk) or abandons a clip download. */
void mg_audio_stop(void);

enum mg_audio_activity mg_audio_activity(void);
/* The type most recently announced with change_data_type. */
void mg_audio_current_format(struct mg_audio_format *fmt);
void mg_audio_set_gain(uint8_t gain);
void mg_audio_init(void);

/* Audio source (mg_audio_dmic.c or mg_audio_synth.c): 10 ms blocks of
 * 160 mono 16-bit samples at 16 kHz. */
#define MG_AUDIO_BLOCK_SAMPLES 160
int mg_audio_src_start(void);
/* Blocks up to timeout_ms for the next block; returns 0 or <0. */
int mg_audio_src_read(int16_t *pcm, int timeout_ms);
void mg_audio_src_stop(void);

#endif
```

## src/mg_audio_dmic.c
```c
/*
 * Copyright (c) Meta Platforms, Inc. and affiliates.
 *
 * Licensed under the Apache License, Version 2.0 (the "License");
 * you may not use this file except in compliance with the License.
 * You may obtain a copy of the License at
 *
 *     http://www.apache.org/licenses/LICENSE-2.0
 *
 * Unless required by applicable law or agreed to in writing, software
 * distributed under the License is distributed on an "AS IS" BASIS,
 * WITHOUT WARRANTIES OR CONDITIONS OF ANY KIND, either express or implied.
 * See the License for the specific language governing permissions and
 * limitations under the License.
 */

#include <errno.h>
#include <string.h>

#include <zephyr/audio/dmic.h>
#include <zephyr/device.h>
#include <zephyr/kernel.h>
#include <zephyr/logging/log.h>

#include "mg_audio.h"

#if defined(CONFIG_MG_DMIC_HW_GAIN_DB) && DT_NODE_HAS_COMPAT(DT_NODELABEL(dmic_dev), nordic_nrf_pdm)
#include <hal/nrf_pdm.h>
#define HW_GAIN 1
#endif

LOG_MODULE_REGISTER(mg_dmic, CONFIG_MG_LOG_LEVEL);

/* The Sense's PDM microphone, 16 kHz mono 16-bit, in 10 ms blocks. */
#define RATE        16000
#define BLOCK_BYTES (MG_AUDIO_BLOCK_SAMPLES * sizeof(int16_t))
#define BLOCKS      8

K_MEM_SLAB_DEFINE_STATIC(dmic_slab, BLOCK_BYTES, BLOCKS, 4);

static const struct device *const dmic = DEVICE_DT_GET(DT_NODELABEL(dmic_dev));
static bool running;
static int skip;

int mg_audio_src_start(void)
{
	struct pcm_stream_cfg stream = {
		.pcm_rate = RATE,
		.pcm_width = 16,
		.block_size = BLOCK_BYTES,
		.mem_slab = &dmic_slab,
	};
	struct dmic_cfg cfg = {
		.io = {
			.min_pdm_clk_freq = 1000000,
			.max_pdm_clk_freq = 3500000,
			.min_pdm_clk_dc = 40,
			.max_pdm_clk_dc = 60,
		},
		.streams = &stream,
		.channel = {
			.req_num_streams = 1,
			.req_num_chan = 1,
		},
	};
	int err;

	if (!device_is_ready(dmic)) {
		return -ENODEV;
	}
	cfg.channel.req_chan_map_lo = dmic_build_channel_map(0, 0, PDM_CHAN_LEFT);
	err = dmic_configure(dmic, &cfg);
	if (err) {
		LOG_ERR("dmic_configure: %d", err);
		return err;
	}
#if defined(HW_GAIN)
	/* The PDM's own gain, 0.5 dB steps around its 0 dB default; the driver
	 * leaves it at 0 dB. Set while stopped, before the start below. */
	nrf_pdm_gain_t g = NRF_PDM_GAIN_DEFAULT + 2 * CONFIG_MG_DMIC_HW_GAIN_DB;

	nrf_pdm_gain_set((NRF_PDM_Type *)DT_REG_ADDR(DT_NODELABEL(dmic_dev)), g, g);
#endif
	err = dmic_trigger(dmic, DMIC_TRIGGER_START);
	if (err) {
		LOG_ERR("dmic start: %d", err);
		return err;
	}
	running = true;
	skip = 2; /* the first 20 ms carry the mic's power-up transient */
	return 0;
}

int mg_audio_src_read(int16_t *pcm, int timeout_ms)
{
	void *buf;
	uint32_t size;
	int err;

	do {
		err = dmic_read(dmic, 0, &buf, &size, timeout_ms);
		if (err) {
			return err;
		}
		if (skip > 0) {
			skip--;
			k_mem_slab_free(&dmic_slab, buf);
			continue;
		}
		break;
	} while (true);
	memcpy(pcm, buf, MIN(size, BLOCK_BYTES));
	if (size < BLOCK_BYTES) {
		memset((uint8_t *)pcm + size, 0, BLOCK_BYTES - size);
	}
	k_mem_slab_free(&dmic_slab, buf);
	return 0;
}

void mg_audio_src_stop(void)
{
	void *buf;
	uint32_t size;

	if (!running) {
		return;
	}
	(void)dmic_trigger(dmic, DMIC_TRIGGER_STOP);
	/* Give back whatever was still queued. */
	while (dmic_read(dmic, 0, &buf, &size, 0) == 0) {
		k_mem_slab_free(&dmic_slab, buf);
	}
	running = false;
}
```

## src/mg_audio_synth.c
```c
/*
 * Copyright (c) Meta Platforms, Inc. and affiliates.
 *
 * Licensed under the Apache License, Version 2.0 (the "License");
 * you may not use this file except in compliance with the License.
 * You may obtain a copy of the License at
 *
 *     http://www.apache.org/licenses/LICENSE-2.0
 *
 * Unless required by applicable law or agreed to in writing, software
 * distributed under the License is distributed on an "AS IS" BASIS,
 * WITHOUT WARRANTIES OR CONDITIONS OF ANY KIND, either express or implied.
 * See the License for the specific language governing permissions and
 * limitations under the License.
 */

#include <errno.h>

#include <zephyr/kernel.h>

#include "mg_audio.h"

/*
 * Synthetic source: a 1 kHz tone (exactly 16 samples per period at 16 kHz)
 * whose level steps every 100 ms, delivered in real time. Simulation and
 * the tests check for it after decoding.
 */

static const int16_t sine16[16] = {
	0, 957, 1768, 2310, 2500, 2310, 1768, 957, 0, -957, -1768, -2310, -2500, -2310, -1768, -957,
};

static int64_t t0;
static uint32_t n;

int mg_audio_src_start(void)
{
	t0 = k_uptime_get();
	n = 0;
	return 0;
}

int mg_audio_src_read(int16_t *pcm, int timeout_ms)
{
	int64_t due = t0 + (int64_t)(n + 1) * 10;
	int64_t now = k_uptime_get();

	if (due - now > timeout_ms) {
		k_sleep(K_MSEC(timeout_ms));
		return -EAGAIN;
	}
	if (due > now) {
		k_sleep(K_MSEC(due - now));
	}
	/* Level cycles through 1/2, 3/4 and full scale every 100 ms. */
	int step = (n / 10) % 3;
	int num = step == 0 ? 2 : (step == 1 ? 3 : 4);

	for (int i = 0; i < MG_AUDIO_BLOCK_SAMPLES; i++) {
		pcm[i] = (int16_t)(sine16[(n * MG_AUDIO_BLOCK_SAMPLES + i) & 15] * num / 4);
	}
	n++;
	return 0;
}

void mg_audio_src_stop(void)
{
}
```

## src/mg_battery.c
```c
/*
 * Copyright (c) Meta Platforms, Inc. and affiliates.
 *
 * Licensed under the Apache License, Version 2.0 (the "License");
 * you may not use this file except in compliance with the License.
 * You may obtain a copy of the License at
 *
 *     http://www.apache.org/licenses/LICENSE-2.0
 *
 * Unless required by applicable law or agreed to in writing, software
 * distributed under the License is distributed on an "AS IS" BASIS,
 * WITHOUT WARRANTIES OR CONDITIONS OF ANY KIND, either express or implied.
 * See the License for the specific language governing permissions and
 * limitations under the License.
 */

#include "mg_battery.h"

#include <zephyr/drivers/adc.h>
#include <zephyr/kernel.h>
#include <zephyr/logging/log.h>

LOG_MODULE_REGISTER(mg_battery, CONFIG_MG_LOG_LEVEL);

/* VBAT on /zephyr,user io-channels, behind a divider of
 * CONFIG_MG_BATTERY_DIVIDER_RATIO. */
static const struct adc_dt_spec vbat = ADC_DT_SPEC_GET_BY_IDX(DT_PATH(zephyr_user), 0);

/* Single-cell LiPo, resting voltage to charge (mV, %). */
static const struct {
	uint16_t mv;
	uint8_t pct;
} curve[] = {
	{4150, 100}, {4050, 90}, {3970, 80}, {3900, 70}, {3840, 60}, {3790, 50},
	{3750, 40},  {3710, 30}, {3670, 20}, {3610, 10}, {3500, 5},  {3300, 0},
};

uint8_t mg_battery_percent_from_mv(int mv)
{
	if (mv >= curve[0].mv) {
		return 100;
	}
	for (size_t i = 1; i < ARRAY_SIZE(curve); i++) {
		if (mv >= curve[i].mv) {
			int span = curve[i - 1].mv - curve[i].mv;

			return curve[i].pct +
			       (curve[i - 1].pct - curve[i].pct) * (mv - curve[i].mv) / span;
		}
	}
	return 0;
}

int mg_battery_read_mv(void)
{
	int16_t raw;
	struct adc_sequence seq = {
		.buffer = &raw,
		.buffer_size = sizeof(raw),
	};
	int err;

	if (!adc_is_ready_dt(&vbat)) {
		return -ENODEV;
	}
	err = adc_channel_setup_dt(&vbat);
	err = err ?: adc_sequence_init_dt(&vbat, &seq);
	err = err ?: adc_read_dt(&vbat, &seq);
	if (err) {
		return err;
	}
	int32_t mv = raw;

	err = adc_raw_to_millivolts_dt(&vbat, &mv);
	if (err) {
		return err;
	}
	return mv * CONFIG_MG_BATTERY_DIVIDER_RATIO;
}
```

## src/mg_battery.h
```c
/*
 * Copyright (c) Meta Platforms, Inc. and affiliates.
 *
 * Licensed under the Apache License, Version 2.0 (the "License");
 * you may not use this file except in compliance with the License.
 * You may obtain a copy of the License at
 *
 *     http://www.apache.org/licenses/LICENSE-2.0
 *
 * Unless required by applicable law or agreed to in writing, software
 * distributed under the License is distributed on an "AS IS" BASIS,
 * WITHOUT WARRANTIES OR CONDITIONS OF ANY KIND, either express or implied.
 * See the License for the specific language governing permissions and
 * limitations under the License.
 */

#ifndef MG_BATTERY_H_
#define MG_BATTERY_H_

#include <stdint.h>

/* Battery voltage in mV, or <0 if it can't be read. */
int mg_battery_read_mv(void);
uint8_t mg_battery_percent_from_mv(int mv);

#endif
```
